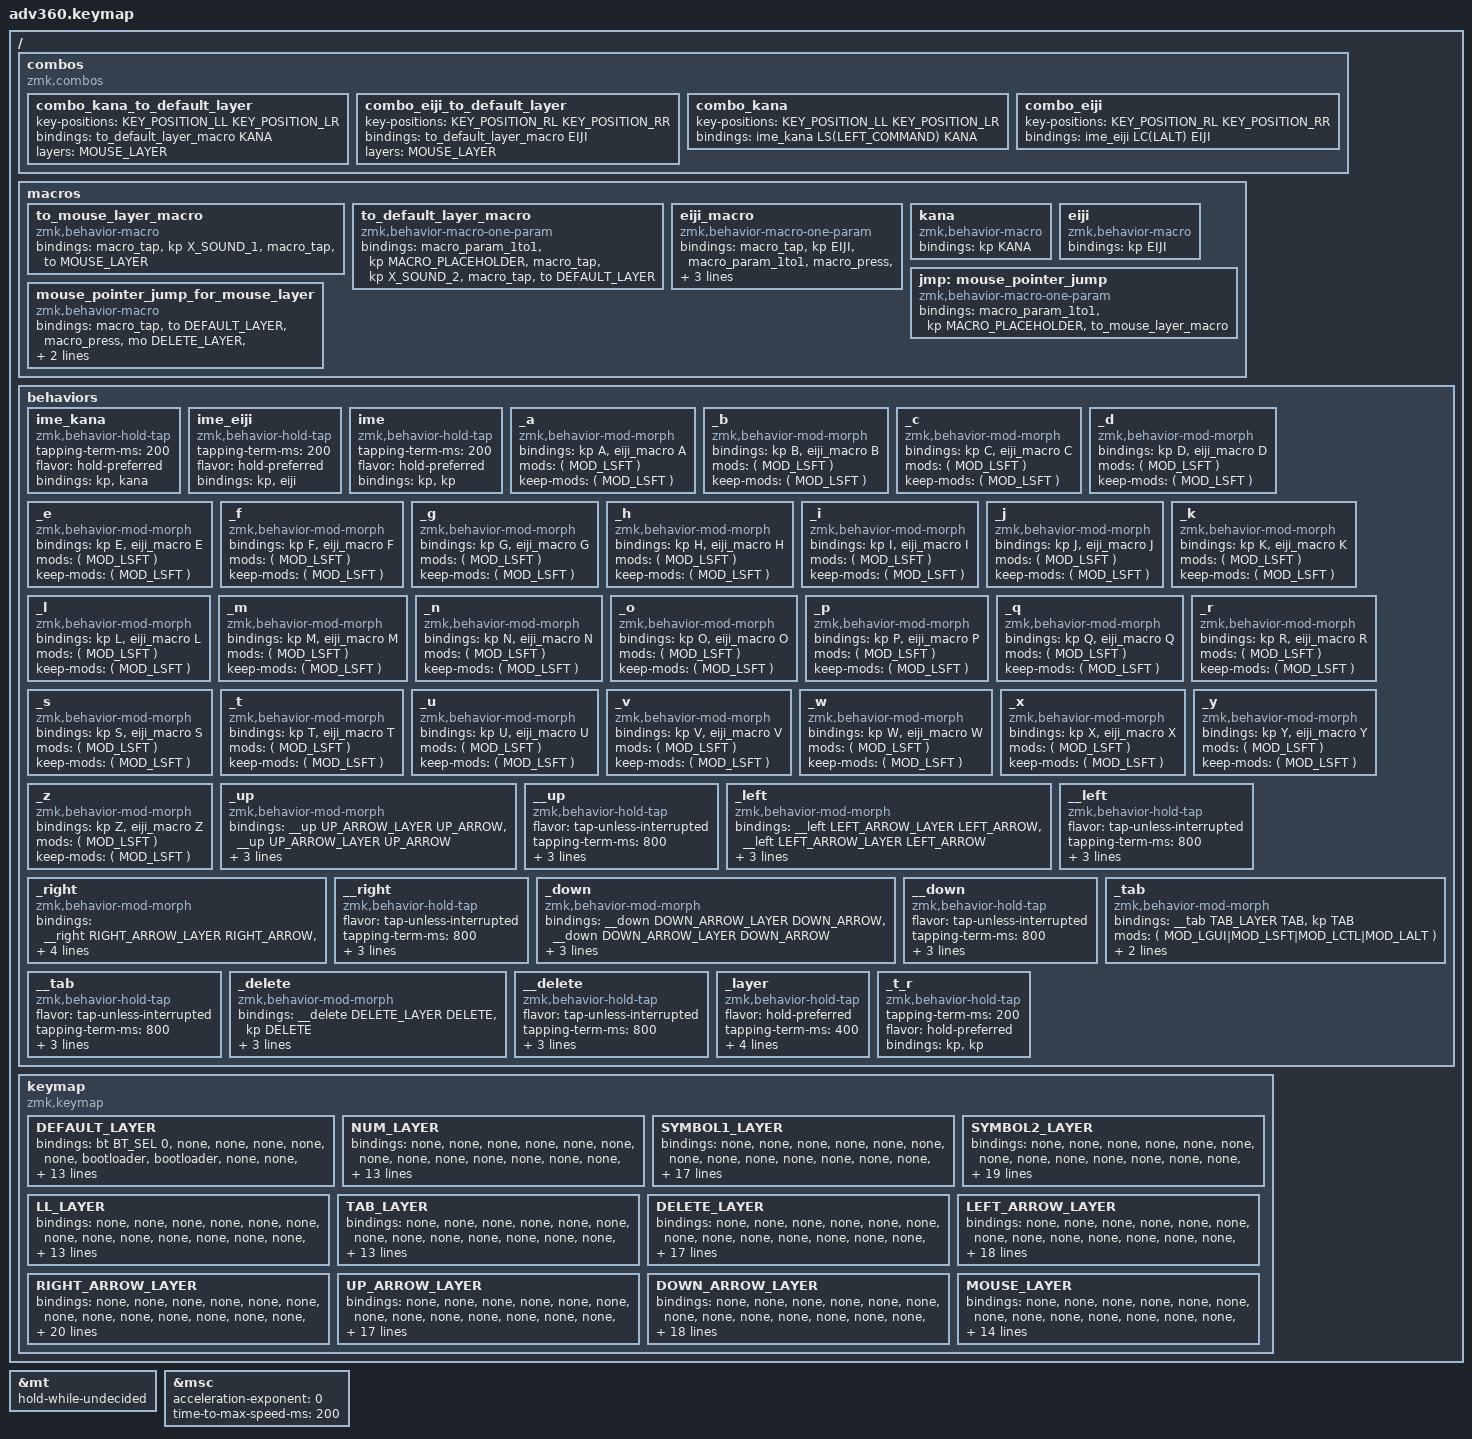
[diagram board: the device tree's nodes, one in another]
#define ZMK_POINTING_DEFAULT_SCRL_VAL 20
#include <behaviors.dtsi>
#include <dt-bindings/zmk/keys.h>
#include <dt-bindings/zmk/bt.h>
#include <dt-bindings/zmk/rgb.h>
#include <dt-bindings/zmk/backlight.h>
#include <dt-bindings/zmk/mouse.h>
#include <dt-bindings/zmk/pointing.h>

// レイヤー
// ------------------------------------
#define DEFAULT_LAYER 0
#define NUM_LAYER 1
#define SYMBOL1_LAYER 2
#define SYMBOL2_LAYER 3
#define LL_LAYER 4
#define TAB_LAYER 5
#define DELETE_LAYER 6
#define LEFT_ARROW_LAYER 7
#define RIGHT_ARROW_LAYER 8
#define UP_ARROW_LAYER 9
#define DOWN_ARROW_LAYER 10
#define MOUSE_LAYER 11

// ------------------------------------
// エイリアス
// ------------------------------------
// 効果音
#define X_SOUND_1 LANGUAGE_3
#define X_SOUND_2 LANGUAGE_4

// 和英
#define EIJI LANGUAGE_2
#define KANA LANGUAGE_1

// 親指
#define T_LL LEFT_SHIFT RETURN
#define T_LR LEFT_COMMAND BACKSPACE

// 和英
#define X_QQ RG(RA(RS(RC(LANGUAGE_8))))
#define X_PP RG(RA(RS(RC(LANGUAGE_9))))

// ------------------------------------
// キー位置
// https://github.com/KinesisCorporation/Adv360-Pro-ZMK/blob/V3.0/assets/key-positions.md
// ------------------------------------
#define KEY_POSITION_LL 65
#define KEY_POSITION_LR 66
#define KEY_POSITION_RL 69
#define KEY_POSITION_RR 70
#define KEY_POSITION_UP_ARROW 56
#define KEY_POSITION_LEFT_ARROW 71
#define KEY_POSITION_DOWN_ARROW 72
#define KEY_POSITION_RIGHT_ARROW 73
#define KEY_POSITION_LEFT_SIDE 0  1  2  3  4  5  6 \
  14 15 16 17 18 19 20 \
  28 29 30 31 32 33 34 \
  46 47 48 49 50 51    \
  60 61 62 63 64
#define KEY_POSITION_RIGHT_SIDE 7  8  9 10 11 12 13 \
  21 22 23 24 25 26 27 \
  39 40 41 42 43 44 45 \
      54 55 56 57 58 59 \
        71 72 73 74 75
#define KEY_POSITION_L_THUMB KEY_POSITION_LL KEY_POSITION_LR

// ------------------------------------
// OSに渡す用ショートカット
// ------------------------------------
#define X_LL_LL KP_N0
#define X_LH_NUM RG(RA(RS(RC(LANGUAGE_5))))
#define X_LH_SYM1 RG(RA(RS(RC(LANGUAGE_6))))
#define X_LH_SYM2 RG(RA(RS(RC(LANGUAGE_7))))

// LL
#define X_LL_AA INTERNATIONAL_1
#define X_LL_ZZ INTERNATIONAL_2
#define X_LL_QQ INTERNATIONAL_3
#define X_LL_NUM INTERNATIONAL_4
#define X_LL_SYM1 INTERNATIONAL_5
#define X_LL_SYM2 INTERNATIONAL_6
#define X_LL_T_LL INTERNATIONAL_7
#define X_LL_T_LR INTERNATIONAL_8
#define X_LL_Q KP_N1
#define X_LL_W KP_N2
#define X_LL_E KP_N3
#define X_LL_R KP_N4
#define X_LL_T KP_N5
#define X_LL_A KP_N6
#define X_LL_S KP_N7
#define X_LL_D KP_N8
#define X_LL_F KP_N9
#define X_LL_G KP_PLUS
#define X_LL_Z KP_EQUAL
#define X_LL_X KP_DOT
#define X_LL_C KP_MINUS
#define X_LL_V KP_SLASH
#define X_LL_B KP_ASTERISK

// TAB: SHIFT ALT
#define X_TAB_AA RS(RA(NON_US_BACKSLASH))
#define X_TAB_ZZ RS(RA(K_APPLICATION))
#define X_TAB_QQ RS(RA(LANGUAGE_5))
#define X_TAB_NUM RS(RA(LANGUAGE_6))
#define X_TAB_SYM1 RS(RA(LANGUAGE_7))
#define X_TAB_SYM2 RS(RA(LANGUAGE_8))
#define X_TAB_T_LL RS(RA(INSERT))
#define X_TAB_T_LR RS(RA(KP_ENTER))
#define X_TAB_Q RS(RA(F13))
#define X_TAB_W RS(RA(F14))
#define X_TAB_E RS(RA(F15))
#define X_TAB_R RS(RA(F16))
#define X_TAB_T RS(RA(F17))
#define X_TAB_A RS(RA(F18))
#define X_TAB_S RS(RA(F19))
#define X_TAB_D RS(RA(F20))
#define X_TAB_F RS(RA(F21))
#define X_TAB_G RS(RA(F22))
#define X_TAB_Z RS(RA(F23))
#define X_TAB_X RS(RA(F24))
#define X_TAB_C RS(RA(NON_US_HASH))
#define X_TAB_V RS(RA(PRINTSCREEN))
#define X_TAB_B RS(RA(PAUSE_BREAK))

// DELETE: SHIFT, COMMAND
#define X_DELETE_AA RS(RG(NON_US_BACKSLASH))
#define X_DELETE_ZZ RS(RG(K_APPLICATION))
#define X_DELETE_QQ RS(RG(LANGUAGE_5))
#define X_DELETE_NUM RS(RG(LANGUAGE_6))
#define X_DELETE_SYM1 RS(RG(LANGUAGE_7))
#define X_DELETE_SYM2 RS(RG(LANGUAGE_8))
#define X_DELETE_T_LL RS(RG(INSERT))
#define X_DELETE_T_LR RS(RG(KP_ENTER))
#define X_DELETE_Q RS(RG(F13))
#define X_DELETE_W RS(RG(F14))
#define X_DELETE_E RS(RG(F15))
#define X_DELETE_R RS(RG(F16))
#define X_DELETE_T RS(RG(F17))
#define X_DELETE_A RS(RG(F18))
#define X_DELETE_S RS(RG(F19))
#define X_DELETE_D RS(RG(F20))
#define X_DELETE_F RS(RG(F21))
#define X_DELETE_G RS(RG(F22))
#define X_DELETE_Z RS(RG(F23))
#define X_DELETE_X RS(RG(F24))
#define X_DELETE_C RS(RG(NON_US_HASH))
#define X_DELETE_V RS(RG(PRINTSCREEN))
#define X_DELETE_B RS(RG(PAUSE_BREAK))

// LEFT_ARROW: ALT, CTRL
#define X_LEFT_ARROW_AA RA(RC(NON_US_BACKSLASH))
#define X_LEFT_ARROW_ZZ RA(RC(K_APPLICATION))
#define X_LEFT_ARROW_QQ RA(RC(LANGUAGE_5))
#define X_LEFT_ARROW_NUM RA(RC(LANGUAGE_6))
#define X_LEFT_ARROW_SYM1 RA(RC(LANGUAGE_7))
#define X_LEFT_ARROW_SYM2 RA(RC(LANGUAGE_8))
#define X_LEFT_ARROW_T_LL RA(RC(INSERT))
#define X_LEFT_ARROW_T_LR RA(RC(KP_ENTER))
#define X_LEFT_ARROW_Q RA(RC(F13))
#define X_LEFT_ARROW_W RA(RC(F14))
#define X_LEFT_ARROW_E RA(RC(F15))
#define X_LEFT_ARROW_R RA(RC(F16))
#define X_LEFT_ARROW_T RA(RC(F17))
#define X_LEFT_ARROW_A RA(RC(F18))
#define X_LEFT_ARROW_S RA(RC(F19))
#define X_LEFT_ARROW_D RA(RC(F20))
#define X_LEFT_ARROW_F RA(RC(F21))
#define X_LEFT_ARROW_G RA(RC(F22))
#define X_LEFT_ARROW_Z RA(RC(F23))
#define X_LEFT_ARROW_X RA(RC(F24))
#define X_LEFT_ARROW_C RA(RC(NON_US_HASH))
#define X_LEFT_ARROW_V RA(RC(PRINTSCREEN))
#define X_LEFT_ARROW_B RA(RC(PAUSE_BREAK))

// RIGHT_ARROW: COMMAND, CTRL
#define X_RIGHT_ARROW_AA RG(RC(NON_US_BACKSLASH))
#define X_RIGHT_ARROW_ZZ RG(RC(K_APPLICATION))
#define X_RIGHT_ARROW_QQ RG(RC(LANGUAGE_5))
#define X_RIGHT_ARROW_NUM RG(RC(LANGUAGE_6))
#define X_RIGHT_ARROW_SYM1 RG(RC(LANGUAGE_7))
#define X_RIGHT_ARROW_SYM2 RG(RC(LANGUAGE_8))
#define X_RIGHT_ARROW_T_LL RG(RC(INSERT))
#define X_RIGHT_ARROW_T_LR RG(RC(KP_ENTER))
#define X_RIGHT_ARROW_Q RG(RC(F13))
#define X_RIGHT_ARROW_W RG(RC(F14))
#define X_RIGHT_ARROW_E RG(RC(F15))
#define X_RIGHT_ARROW_R RG(RC(F16))
#define X_RIGHT_ARROW_T RG(RC(F17))
#define X_RIGHT_ARROW_A RG(RC(F18))
#define X_RIGHT_ARROW_S RG(RC(F19))
#define X_RIGHT_ARROW_D RG(RC(F20))
#define X_RIGHT_ARROW_F RG(RC(F21))
#define X_RIGHT_ARROW_G RG(RC(F22))
#define X_RIGHT_ARROW_Z RG(RC(F23))
#define X_RIGHT_ARROW_X RG(RC(F24))
#define X_RIGHT_ARROW_C RG(RC(NON_US_HASH))
#define X_RIGHT_ARROW_V RG(RC(PRINTSCREEN))
#define X_RIGHT_ARROW_B RG(RC(PAUSE_BREAK))

// UP_ARROW: SHIFT, CTRL
#define X_UP_ARROW_AA RS(RC(NON_US_BACKSLASH))
#define X_UP_ARROW_ZZ RS(RC(K_APPLICATION))
#define X_UP_ARROW_QQ RS(RC(LANGUAGE_5))
#define X_UP_ARROW_NUM RS(RC(LANGUAGE_6))
#define X_UP_ARROW_SYM1 RS(RC(LANGUAGE_7))
#define X_UP_ARROW_SYM2 RS(RC(LANGUAGE_8))
#define X_UP_ARROW_T_LL RS(RC(INSERT))
#define X_UP_ARROW_T_LR RS(RC(KP_ENTER))
#define X_UP_ARROW_Q RS(RC(F13))
#define X_UP_ARROW_W RS(RC(F14))
#define X_UP_ARROW_E RS(RC(F15))
#define X_UP_ARROW_R RS(RC(F16))
#define X_UP_ARROW_T RS(RC(F17))
#define X_UP_ARROW_A RS(RC(F18))
#define X_UP_ARROW_S RS(RC(F19))
#define X_UP_ARROW_D RS(RC(F20))
#define X_UP_ARROW_F RS(RC(F21))
#define X_UP_ARROW_G RS(RC(F22))
#define X_UP_ARROW_Z RS(RC(F23))
#define X_UP_ARROW_X RS(RC(F24))
#define X_UP_ARROW_C RS(RC(NON_US_HASH))
#define X_UP_ARROW_V RS(RC(PRINTSCREEN))
#define X_UP_ARROW_B RS(RC(PAUSE_BREAK))

// DOWN_ARROW: COMMAND, ALT
#define X_DOWN_ARROW_AA RG(RA(NON_US_BACKSLASH))
#define X_DOWN_ARROW_ZZ RG(RA(K_APPLICATION))
#define X_DOWN_ARROW_QQ RG(RA(LANGUAGE_5))
#define X_DOWN_ARROW_NUM RG(RA(LANGUAGE_6))
#define X_DOWN_ARROW_SYM1 RG(RA(LANGUAGE_7))
#define X_DOWN_ARROW_SYM2 RG(RA(LANGUAGE_8))
#define X_DOWN_ARROW_T_LL RG(RA(INSERT))
#define X_DOWN_ARROW_T_LR RG(RA(KP_ENTER))
#define X_DOWN_ARROW_Q RG(RA(F13))
#define X_DOWN_ARROW_W RG(RA(F14))
#define X_DOWN_ARROW_E RG(RA(F15))
#define X_DOWN_ARROW_R RG(RA(F16))
#define X_DOWN_ARROW_T RG(RA(F17))
#define X_DOWN_ARROW_A RG(RA(F18))
#define X_DOWN_ARROW_S RG(RA(F19))
#define X_DOWN_ARROW_D RG(RA(F20))
#define X_DOWN_ARROW_F RG(RA(F21))
#define X_DOWN_ARROW_G RG(RA(F22))
#define X_DOWN_ARROW_Z RG(RA(F23))
#define X_DOWN_ARROW_X RG(RA(F24))
#define X_DOWN_ARROW_C RG(RA(NON_US_HASH))
#define X_DOWN_ARROW_V RG(RA(PRINTSCREEN))
#define X_DOWN_ARROW_B RG(RA(PAUSE_BREAK))

// ------------------------------------
// https://github.com/zmkfirmware/zmk/pull/1811
&mt {
  hold-while-undecided;
};
&msc {
  acceleration-exponent = <0>;
  time-to-max-speed-ms = <200>;
};
/ {
  combos {
    compatible = "zmk,combos";

    combo_kana_to_default_layer {
      key-positions = <KEY_POSITION_LL KEY_POSITION_LR>;
      bindings = <&to_default_layer_macro KANA>;
      layers = <MOUSE_LAYER>;
    };
    combo_eiji_to_default_layer {
      key-positions = <KEY_POSITION_RL KEY_POSITION_RR>;
      bindings = <&to_default_layer_macro EIJI>;
      layers = <MOUSE_LAYER>;
    };
    combo_kana {
      key-positions = <KEY_POSITION_LL KEY_POSITION_LR>;
      bindings = <&ime_kana LS(LEFT_COMMAND) KANA>;
    };
    combo_eiji {
      key-positions = <KEY_POSITION_RL KEY_POSITION_RR>;
      bindings = <&ime_eiji LC(LALT) EIJI>;
    };
  };
  macros {

    // レイヤー移動で効果音を鳴らす
    to_mouse_layer_macro: to_mouse_layer_macro {
      compatible = "zmk,behavior-macro";
      #binding-cells = <0>;
      bindings = <&macro_tap &kp X_SOUND_1>, <&macro_tap &to MOUSE_LAYER>;
    };

    // レイヤー移動で効果音を鳴らす
    to_default_layer_macro: to_default_layer_macro {
      compatible = "zmk,behavior-macro-one-param";
      #binding-cells = <1>;
      bindings = <&macro_param_1to1 &kp MACRO_PLACEHOLDER>, <&macro_tap &kp X_SOUND_2>, <&macro_tap &to DEFAULT_LAYER>;
    };

    // 英語入力に切り替える
    eiji_macro: eiji_macro {
      compatible = "zmk,behavior-macro-one-param";
      #binding-cells = <1>;
      bindings = <&macro_tap &kp EIJI>, <&macro_param_1to1>, <&macro_press &kp MACRO_PLACEHOLDER>, <&macro_pause_for_release>, <&macro_param_1to1>, <&macro_release &kp MACRO_PLACEHOLDER>;
    };
    kana: kana {
      compatible = "zmk,behavior-macro";
      #binding-cells = <0>;
      bindings = <&kp KANA>;
    };
    eiji: eiji {
      compatible = "zmk,behavior-macro";
      #binding-cells = <0>;
      bindings = <&kp EIJI>;
    };

    // マウスのカーソルをジャンプして マウスレイヤーに切り替え
    jmp: mouse_pointer_jump {
      compatible = "zmk,behavior-macro-one-param";
      #binding-cells = <1>;
      bindings = <&macro_param_1to1 &kp MACRO_PLACEHOLDER>, <&to_mouse_layer_macro>;
    };
    mouse_pointer_jump_for_mouse_layer: mouse_pointer_jump_for_mouse_layer {
      compatible = "zmk,behavior-macro";
      #binding-cells = <0>;
      bindings = <&macro_tap &to DEFAULT_LAYER>, <&macro_press &mo DELETE_LAYER>, <&macro_pause_for_release>, <&macro_release &mo DELETE_LAYER>;
    };
  };
  behaviors {
    ime_kana: ime_kana {
      compatible = "zmk,behavior-hold-tap";
      #binding-cells = <2>;
      tapping-term-ms = <200>;
      flavor = "hold-preferred";
      bindings = <&kp>, <&kana>;
    };
    ime_eiji: ime_eiji {
      compatible = "zmk,behavior-hold-tap";
      #binding-cells = <2>;
      tapping-term-ms = <200>;
      flavor = "hold-preferred";
      bindings = <&kp>, <&eiji>;
    };

    // comboから呼ばれる
    ime: ime {
      compatible = "zmk,behavior-hold-tap";
      #binding-cells = <2>;
      tapping-term-ms = <200>;
      flavor = "hold-preferred";
      bindings = <&kp>, <&kp>;
    };
    _a: _a {
      compatible = "zmk,behavior-mod-morph";
      #binding-cells = <0>;
      bindings = <&kp A>, <&eiji_macro A>;
      mods = <( MOD_LSFT )>;
      keep-mods = <( MOD_LSFT )>;
    };
    _b: _b {
      compatible = "zmk,behavior-mod-morph";
      #binding-cells = <0>;
      bindings = <&kp B>, <&eiji_macro B>;
      mods = <( MOD_LSFT )>;
      keep-mods = <( MOD_LSFT )>;
    };
    _c: _c {
      compatible = "zmk,behavior-mod-morph";
      #binding-cells = <0>;
      bindings = <&kp C>, <&eiji_macro C>;
      mods = <( MOD_LSFT )>;
      keep-mods = <( MOD_LSFT )>;
    };
    _d: _d {
      compatible = "zmk,behavior-mod-morph";
      #binding-cells = <0>;
      bindings = <&kp D>, <&eiji_macro D>;
      mods = <( MOD_LSFT )>;
      keep-mods = <( MOD_LSFT )>;
    };
    _e: _e {
      compatible = "zmk,behavior-mod-morph";
      #binding-cells = <0>;
      bindings = <&kp E>, <&eiji_macro E>;
      mods = <( MOD_LSFT )>;
      keep-mods = <( MOD_LSFT )>;
    };
    _f: _f {
      compatible = "zmk,behavior-mod-morph";
      #binding-cells = <0>;
      bindings = <&kp F>, <&eiji_macro F>;
      mods = <( MOD_LSFT )>;
      keep-mods = <( MOD_LSFT )>;
    };
    _g: _g {
      compatible = "zmk,behavior-mod-morph";
      #binding-cells = <0>;
      bindings = <&kp G>, <&eiji_macro G>;
      mods = <( MOD_LSFT )>;
      keep-mods = <( MOD_LSFT )>;
    };
    _h: _h {
      compatible = "zmk,behavior-mod-morph";
      #binding-cells = <0>;
      bindings = <&kp H>, <&eiji_macro H>;
      mods = <( MOD_LSFT )>;
      keep-mods = <( MOD_LSFT )>;
    };
    _i: _i {
      compatible = "zmk,behavior-mod-morph";
      #binding-cells = <0>;
      bindings = <&kp I>, <&eiji_macro I>;
      mods = <( MOD_LSFT )>;
      keep-mods = <( MOD_LSFT )>;
    };
    _j: _j {
      compatible = "zmk,behavior-mod-morph";
      #binding-cells = <0>;
      bindings = <&kp J>, <&eiji_macro J>;
      mods = <( MOD_LSFT )>;
      keep-mods = <( MOD_LSFT )>;
    };
    _k: _k {
      compatible = "zmk,behavior-mod-morph";
      #binding-cells = <0>;
      bindings = <&kp K>, <&eiji_macro K>;
      mods = <( MOD_LSFT )>;
      keep-mods = <( MOD_LSFT )>;
    };
    _l: _l {
      compatible = "zmk,behavior-mod-morph";
      #binding-cells = <0>;
      bindings = <&kp L>, <&eiji_macro L>;
      mods = <( MOD_LSFT )>;
      keep-mods = <( MOD_LSFT )>;
    };
    _m: _m {
      compatible = "zmk,behavior-mod-morph";
      #binding-cells = <0>;
      bindings = <&kp M>, <&eiji_macro M>;
      mods = <( MOD_LSFT )>;
      keep-mods = <( MOD_LSFT )>;
    };
    _n: _n {
      compatible = "zmk,behavior-mod-morph";
      #binding-cells = <0>;
      bindings = <&kp N>, <&eiji_macro N>;
      mods = <( MOD_LSFT )>;
      keep-mods = <( MOD_LSFT )>;
    };
    _o: _o {
      compatible = "zmk,behavior-mod-morph";
      #binding-cells = <0>;
      bindings = <&kp O>, <&eiji_macro O>;
      mods = <( MOD_LSFT )>;
      keep-mods = <( MOD_LSFT )>;
    };
    _p: _p {
      compatible = "zmk,behavior-mod-morph";
      #binding-cells = <0>;
      bindings = <&kp P>, <&eiji_macro P>;
      mods = <( MOD_LSFT )>;
      keep-mods = <( MOD_LSFT )>;
    };
    _q: _q {
      compatible = "zmk,behavior-mod-morph";
      #binding-cells = <0>;
      bindings = <&kp Q>, <&eiji_macro Q>;
      mods = <( MOD_LSFT )>;
      keep-mods = <( MOD_LSFT )>;
    };
    _r: _r {
      compatible = "zmk,behavior-mod-morph";
      #binding-cells = <0>;
      bindings = <&kp R>, <&eiji_macro R>;
      mods = <( MOD_LSFT )>;
      keep-mods = <( MOD_LSFT )>;
    };
    _s: _s {
      compatible = "zmk,behavior-mod-morph";
      #binding-cells = <0>;
      bindings = <&kp S>, <&eiji_macro S>;
      mods = <( MOD_LSFT )>;
      keep-mods = <( MOD_LSFT )>;
    };
    _t: _t {
      compatible = "zmk,behavior-mod-morph";
      #binding-cells = <0>;
      bindings = <&kp T>, <&eiji_macro T>;
      mods = <( MOD_LSFT )>;
      keep-mods = <( MOD_LSFT )>;
    };
    _u: _u {
      compatible = "zmk,behavior-mod-morph";
      #binding-cells = <0>;
      bindings = <&kp U>, <&eiji_macro U>;
      mods = <( MOD_LSFT )>;
      keep-mods = <( MOD_LSFT )>;
    };
    _v: _v {
      compatible = "zmk,behavior-mod-morph";
      #binding-cells = <0>;
      bindings = <&kp V>, <&eiji_macro V>;
      mods = <( MOD_LSFT )>;
      keep-mods = <( MOD_LSFT )>;
    };
    _w: _w {
      compatible = "zmk,behavior-mod-morph";
      #binding-cells = <0>;
      bindings = <&kp W>, <&eiji_macro W>;
      mods = <( MOD_LSFT )>;
      keep-mods = <( MOD_LSFT )>;
    };
    _x: _x {
      compatible = "zmk,behavior-mod-morph";
      #binding-cells = <0>;
      bindings = <&kp X>, <&eiji_macro X>;
      mods = <( MOD_LSFT )>;
      keep-mods = <( MOD_LSFT )>;
    };
    _y: _y {
      compatible = "zmk,behavior-mod-morph";
      #binding-cells = <0>;
      bindings = <&kp Y>, <&eiji_macro Y>;
      mods = <( MOD_LSFT )>;
      keep-mods = <( MOD_LSFT )>;
    };
    _z: _z {
      compatible = "zmk,behavior-mod-morph";
      #binding-cells = <0>;
      bindings = <&kp Z>, <&eiji_macro Z>;
      mods = <( MOD_LSFT )>;
      keep-mods = <( MOD_LSFT )>;
    };
    _up: _up {
      compatible = "zmk,behavior-mod-morph";
      #binding-cells = <0>;
      bindings = <&__up UP_ARROW_LAYER UP_ARROW>, <&__up UP_ARROW_LAYER UP_ARROW>;
      mods = <( MOD_LGUI|MOD_LSFT|MOD_LCTL|MOD_LALT )>;
      keep-mods = <( MOD_LGUI|MOD_LSFT|MOD_LCTL|MOD_LALT )>;
    };
    __up: __up {
      compatible = "zmk,behavior-hold-tap";
      #binding-cells = <2>;
      flavor = "tap-unless-interrupted";
      tapping-term-ms = <800>;
      bindings = <&mo>, <&kp>;
      hold-trigger-key-positions = <KEY_POSITION_LEFT_SIDE KEY_POSITION_L_THUMB KEY_POSITION_LEFT_ARROW KEY_POSITION_RIGHT_ARROW>;
    };
    _left: _left {
      compatible = "zmk,behavior-mod-morph";
      #binding-cells = <0>;
      bindings = <&__left LEFT_ARROW_LAYER LEFT_ARROW>, <&__left LEFT_ARROW_LAYER LEFT_ARROW>;
      mods = <( MOD_LGUI|MOD_LSFT|MOD_LCTL|MOD_LALT )>;
      keep-mods = <( MOD_LGUI|MOD_LSFT|MOD_LCTL|MOD_LALT )>;
    };
    __left: __left {
      compatible = "zmk,behavior-hold-tap";
      #binding-cells = <2>;
      flavor = "tap-unless-interrupted";
      tapping-term-ms = <800>;
      bindings = <&mo>, <&kp>;
      hold-trigger-key-positions = <KEY_POSITION_LEFT_SIDE KEY_POSITION_L_THUMB KEY_POSITION_DOWN_ARROW KEY_POSITION_RIGHT_ARROW>;
    };
    _right: _right {
      compatible = "zmk,behavior-mod-morph";
      #binding-cells = <0>;
      bindings = <&__right RIGHT_ARROW_LAYER RIGHT_ARROW>, <&__right RIGHT_ARROW_LAYER RIGHT_ARROW>;
      mods = <( MOD_LGUI|MOD_LSFT|MOD_LCTL|MOD_LALT )>;
      keep-mods = <( MOD_LGUI|MOD_LSFT|MOD_LCTL|MOD_LALT )>;
    };
    __right: __right {
      compatible = "zmk,behavior-hold-tap";
      #binding-cells = <2>;
      flavor = "tap-unless-interrupted";
      tapping-term-ms = <800>;
      bindings = <&mo>, <&kp>;
      hold-trigger-key-positions = <KEY_POSITION_LEFT_SIDE KEY_POSITION_L_THUMB KEY_POSITION_DOWN_ARROW KEY_POSITION_LEFT_ARROW>;
    };
    _down: _down {
      compatible = "zmk,behavior-mod-morph";
      #binding-cells = <0>;
      bindings = <&__down DOWN_ARROW_LAYER DOWN_ARROW>, <&__down DOWN_ARROW_LAYER DOWN_ARROW>;
      mods = <( MOD_LGUI|MOD_LSFT|MOD_LCTL|MOD_LALT )>;
      keep-mods = <( MOD_LGUI|MOD_LSFT|MOD_LCTL|MOD_LALT )>;
    };
    __down: __down {
      compatible = "zmk,behavior-hold-tap";
      #binding-cells = <2>;
      flavor = "tap-unless-interrupted";
      tapping-term-ms = <800>;
      bindings = <&mo>, <&kp>;
      hold-trigger-key-positions = <KEY_POSITION_LEFT_SIDE KEY_POSITION_L_THUMB KEY_POSITION_LEFT_ARROW KEY_POSITION_RIGHT_ARROW>;
    };
    _tab: _tab {
      compatible = "zmk,behavior-mod-morph";
      #binding-cells = <0>;
      bindings = <&__tab TAB_LAYER TAB>, <&kp TAB>;
      mods = <( MOD_LGUI|MOD_LSFT|MOD_LCTL|MOD_LALT )>;
      keep-mods = <( MOD_LGUI|MOD_LSFT|MOD_LCTL|MOD_LALT )>;
    };
    __tab: __tab {
      compatible = "zmk,behavior-hold-tap";
      #binding-cells = <2>;
      flavor = "tap-unless-interrupted";
      tapping-term-ms = <800>;
      bindings = <&mo>, <&kp>;
      hold-trigger-key-positions = <KEY_POSITION_LEFT_SIDE KEY_POSITION_L_THUMB>;
    };
    _delete: _delete {
      compatible = "zmk,behavior-mod-morph";
      #binding-cells = <0>;
      bindings = <&__delete DELETE_LAYER DELETE>, <&kp DELETE>;
      mods = <( MOD_LGUI|MOD_LSFT|MOD_LCTL|MOD_LALT )>;
      keep-mods = <( MOD_LGUI|MOD_LSFT|MOD_LCTL|MOD_LALT )>;
    };
    __delete: __delete {
      compatible = "zmk,behavior-hold-tap";
      #binding-cells = <2>;
      flavor = "tap-unless-interrupted";
      tapping-term-ms = <800>;
      bindings = <&mo>, <&kp>;
      hold-trigger-key-positions = <KEY_POSITION_LEFT_SIDE KEY_POSITION_L_THUMB>;
    };
    _layer: _layer {
      compatible = "zmk,behavior-hold-tap";
      #binding-cells = <2>;
      flavor = "hold-preferred";
      tapping-term-ms = <400>;
      quick-tap-ms = <200>;
      bindings = <&mo>, <&kp>;
      hold-trigger-key-positions = <KEY_POSITION_RIGHT_SIDE 62 63 64>;
    };
    _t_r: _t_r {
      compatible = "zmk,behavior-hold-tap";
      #binding-cells = <2>;
      tapping-term-ms = <200>;
      flavor = "hold-preferred";
      bindings = <&kp>, <&kp>;
    };
  };
  keymap {
    compatible = "zmk,keymap";

    DEFAULT_LAYER {
      bindings = <
        &bt BT_SEL 0   &none   &none                             &none                             &none                        &none   &bootloader                                                                                         &bootloader   &none   &none    &none    &none     &none                  &bt BT_SEL 1
        &kp X_QQ       &_q     &_w                               &_e                               &_r                          &_t     &none                                                                                               &none         &_y     &_u      &_i      &_o       &_p                    &kp X_PP
        &kp SPACE      &_a     &_s                               &_d                               &_f                          &_g     &none                    &none      &none   &none   &none                                           &none         &_h     &_j      &_k      &_l       &lt LL_LAYER X_LL_LL   &kp BACKSPACE
        &kp ESCAPE     &_z     &_x                               &_c                               &_v                          &_b                                         &none   &none                                                                 &_n     &_m      &_up     &_tab     &_delete               &kp RETURN
        &none          &none   &_layer SYMBOL2_LAYER X_LH_SYM2   &_layer SYMBOL1_LAYER X_LH_SYM1   &_layer NUM_LAYER X_LH_NUM                         &mt T_LL   &mt T_LR   &none   &none   &_t_r LEFT_ALT ESC   &_t_r LEFT_CONTROL SPACE                         &_left   &_down   &_right   &none                  &none
      >;
    };
    NUM_LAYER {
      bindings = <
        &none   &none   &none     &none        &none   &none   &none                                                                                         &none   &none            &none            &none            &none            &none   &none
        &none   &none   &none     &none        &none   &none   &none                                                                                         &none   &none            &eiji_macro N7   &eiji_macro N8   &eiji_macro N9   &none   &none
        &none   &none   &none     &none        &none   &none   &none              &none      &none   &none   &none                                           &none   &none            &eiji_macro N4   &eiji_macro N5   &eiji_macro N6   &none   &none
        &none   &none   &none     &none        &none   &none                                 &none   &none                                                           &eiji_macro N0   &eiji_macro N1   &eiji_macro N2   &eiji_macro N3   &none   &none
        &none   &none   &kp TAB   &kp RETURN   &none                   &mt T_LL   &mt T_LR   &none   &none   &_t_r LEFT_ALT ESC   &_t_r LEFT_CONTROL SPACE                            &none            &none            &none            &none   &none
      >;
    };
    SYMBOL1_LAYER {
      bindings = <
        &none   &none   &none           &none   &none        &none   &none                                                                                         &none   &none                       &none                      &none                   &none                     &none                   &none
        &none   &none   &none           &none   &none        &none   &none                                                                                         &none   &eiji_macro UNDERSCORE      &eiji_macro PIPE           &eiji_macro AMPERSAND   &eiji_macro EXCLAMATION   &eiji_macro QUESTION    &none
        &none   &none   &none           &none   &none        &none   &none              &none      &none   &none   &none                                           &none   &eiji_macro HASH            &eiji_macro COMMA          &eiji_macro PERIOD      &eiji_macro SEMICOLON     &eiji_macro COLON       &eiji_macro AT_SIGN
        &none   &none   &none           &none   &none        &none                                 &none   &none                                                           &eiji_macro DOUBLE_QUOTES   &eiji_macro SINGLE_QUOTE   &eiji_macro GRAVE       &eiji_macro SLASH         &eiji_macro BACKSLASH   &none
        &none   &none   &kp BACKSPACE   &none   &kp DELETE                   &mt T_LL   &mt T_LR   &none   &none   &_t_r LEFT_ALT ESC   &_t_r LEFT_CONTROL SPACE                                       &none                      &none                   &none                     &none                   &none
      >;
    };
    SYMBOL2_LAYER {
      bindings = <
        &none   &none   &none   &none       &none      &none   &none                                                                                         &none   &none               &none                   &none                      &none                      &none                       &none
        &none   &none   &none   &none       &none      &none   &none                                                                                         &none   &eiji_macro CARET   &eiji_macro LESS_THAN   &eiji_macro GREATER_THAN   &eiji_macro LEFT_BRACKET   &eiji_macro RIGHT_BRACKET   &none
        &none   &none   &none   &none       &none      &none   &none              &none      &none   &none   &none                                           &none   &eiji_macro EQUAL   &eiji_macro PLUS        &eiji_macro MINUS          &eiji_macro ASTERISK       &eiji_macro PERCENT         &eiji_macro DOLLAR
        &none   &none   &none   &none       &none      &none                                 &none   &none                                                           &eiji_macro TILDE   &eiji_macro LPAR        &eiji_macro RPAR           &eiji_macro LEFT_BRACE     &eiji_macro RIGHT_BRACE     &none
        &none   &none   &none   &kp LCTRL   &kp LALT                   &mt T_LL   &mt T_LR   &none   &none   &_t_r LEFT_ALT ESC   &_t_r LEFT_CONTROL SPACE                               &none                   &none                      &none                      &none                       &none
      >;
    };
    LL_LAYER {
      bindings = <
        &none         &none        &none           &none           &none          &none        &none                                                                   &none   &none   &none   &none   &none   &none   &none
        &kp X_LL_QQ   &kp X_LL_Q   &kp X_LL_W      &kp X_LL_E      &kp X_LL_R     &kp X_LL_T   &none                                                                   &none   &none   &none   &none   &none   &none   &none
        &kp X_LL_AA   &kp X_LL_A   &kp X_LL_S      &kp X_LL_D      &kp X_LL_F     &kp X_LL_G   &none                   &none           &none   &none   &none           &none   &none   &none   &none   &none   &none   &none
        &kp X_LL_ZZ   &kp X_LL_Z   &kp X_LL_X      &kp X_LL_C      &kp X_LL_V     &kp X_LL_B                                           &none   &none                           &none   &none   &none   &none   &none   &none
        &none         &none        &kp X_LL_SYM2   &kp X_LL_SYM1   &kp X_LL_NUM                        &kp X_LL_T_LL   &kp X_LL_T_LR   &none   &none   &none   &none                   &none   &none   &none   &none   &none
      >;
    };
    TAB_LAYER {
      bindings = <
        &none          &none         &none            &none            &none           &none         &none                                                                     &none   &none   &none   &none   &none   &none   &none
        &kp X_TAB_QQ   &kp X_TAB_Q   &kp X_TAB_W      &kp X_TAB_E      &kp X_TAB_R     &kp X_TAB_T   &none                                                                     &none   &none   &none   &none   &none   &none   &none
        &kp X_TAB_AA   &kp X_TAB_A   &kp X_TAB_S      &kp X_TAB_D      &kp X_TAB_F     &kp X_TAB_G   &none                    &none            &none   &none   &none           &none   &none   &none   &none   &none   &none   &none
        &kp X_TAB_ZZ   &kp X_TAB_Z   &kp X_TAB_X      &kp X_TAB_C      &kp X_TAB_V     &kp X_TAB_B                                             &none   &none                           &none   &none   &none   &none   &none   &none
        &none          &none         &kp X_TAB_SYM2   &kp X_TAB_SYM1   &kp X_TAB_NUM                         &kp X_TAB_T_LL   &kp X_TAB_T_LR   &none   &none   &none   &none                   &none   &none   &none   &none   &none
      >;
    };
    DELETE_LAYER {
      bindings = <
        &none              &none             &none                &none                &none               &none             &none                                                                             &none   &none   &none   &none   &none   &none   &none
        &jmp X_DELETE_QQ   &jmp X_DELETE_Q   &jmp X_DELETE_W      &jmp X_DELETE_E      &jmp X_DELETE_R     &jmp X_DELETE_T   &none                                                                             &none   &none   &none   &none   &none   &none   &none
        &jmp X_DELETE_AA   &jmp X_DELETE_A   &jmp X_DELETE_S      &jmp X_DELETE_D      &jmp X_DELETE_F     &jmp X_DELETE_G   &none                        &none                &none   &none   &none           &none   &none   &none   &none   &none   &none   &none
        &jmp X_DELETE_ZZ   &jmp X_DELETE_Z   &jmp X_DELETE_X      &jmp X_DELETE_C      &jmp X_DELETE_V     &jmp X_DELETE_B                                                     &none   &none                           &none   &none   &none   &none   &none   &none
        &none              &none             &jmp X_DELETE_SYM2   &jmp X_DELETE_SYM1   &jmp X_DELETE_NUM                             &jmp X_DELETE_T_LL   &jmp X_DELETE_T_LR   &none   &none   &none   &none                   &none   &none   &none   &none   &none
      >;
    };
    LEFT_ARROW_LAYER {
      bindings = <
        &none                 &none                &none                   &none                   &none                  &none                &none                                                                                   &none   &none   &none   &none      &none            &none   &none
        &kp X_LEFT_ARROW_QQ   &kp X_LEFT_ARROW_Q   &kp X_LEFT_ARROW_W      &kp X_LEFT_ARROW_E      &kp X_LEFT_ARROW_R     &kp X_LEFT_ARROW_T   &none                                                                                   &none   &none   &none   &none      &none            &none   &none
        &kp X_LEFT_ARROW_AA   &kp X_LEFT_ARROW_A   &kp X_LEFT_ARROW_S      &kp X_LEFT_ARROW_D      &kp X_LEFT_ARROW_F     &kp X_LEFT_ARROW_G   &none                           &none                   &none   &none   &none           &none   &none   &none   &none      &none            &none   &none
        &kp X_LEFT_ARROW_ZZ   &kp X_LEFT_ARROW_Z   &kp X_LEFT_ARROW_X      &kp X_LEFT_ARROW_C      &kp X_LEFT_ARROW_V     &kp X_LEFT_ARROW_B                                                           &none   &none                           &none   &none   &none      &none            &none   &none
        &none                 &none                &kp X_LEFT_ARROW_SYM2   &kp X_LEFT_ARROW_SYM1   &kp X_LEFT_ARROW_NUM                                &kp X_LEFT_ARROW_T_LL   &kp X_LEFT_ARROW_T_LR   &none   &none   &none   &none                   &none   &kp HOME   &msc SCRL_LEFT   &none   &none
      >;
    };
    RIGHT_ARROW_LAYER {
      bindings = <
        &none                  &none                 &none                    &none                    &none                   &none                 &none                                                                                     &none   &none   &none             &none     &none   &none   &none
        &kp X_RIGHT_ARROW_QQ   &kp X_RIGHT_ARROW_Q   &kp X_RIGHT_ARROW_W      &kp X_RIGHT_ARROW_E      &kp X_RIGHT_ARROW_R     &kp X_RIGHT_ARROW_T   &none                                                                                     &none   &none   &none             &none     &none   &none   &none
        &kp X_RIGHT_ARROW_AA   &kp X_RIGHT_ARROW_A   &kp X_RIGHT_ARROW_S      &kp X_RIGHT_ARROW_D      &kp X_RIGHT_ARROW_F     &kp X_RIGHT_ARROW_G   &none                            &none                    &none   &none   &none           &none   &none   &none             &none     &none   &none   &none
        &kp X_RIGHT_ARROW_ZZ   &kp X_RIGHT_ARROW_Z   &kp X_RIGHT_ARROW_X      &kp X_RIGHT_ARROW_C      &kp X_RIGHT_ARROW_V     &kp X_RIGHT_ARROW_B                                                             &none   &none                           &none   &none             &none     &none   &none   &none
        &none                  &none                 &kp X_RIGHT_ARROW_SYM2   &kp X_RIGHT_ARROW_SYM1   &kp X_RIGHT_ARROW_NUM                                 &kp X_RIGHT_ARROW_T_LL   &kp X_RIGHT_ARROW_T_LR   &none   &none   &none   &none                   &msc SCRL_RIGHT   &kp END   &none   &none   &none
      >;
    };
    UP_ARROW_LAYER {
      bindings = <
        &none               &none              &none                 &none                 &none                &none              &none                                                                               &none   &none   &none         &none   &none          &none   &none
        &kp X_UP_ARROW_QQ   &kp X_UP_ARROW_Q   &kp X_UP_ARROW_W      &kp X_UP_ARROW_E      &kp X_UP_ARROW_R     &kp X_UP_ARROW_T   &none                                                                               &none   &none   &none         &none   &none          &none   &none
        &kp X_UP_ARROW_AA   &kp X_UP_ARROW_A   &kp X_UP_ARROW_S      &kp X_UP_ARROW_D      &kp X_UP_ARROW_F     &kp X_UP_ARROW_G   &none                         &none                 &none   &none   &none           &none   &none   &none         &none   &none          &none   &none
        &kp X_UP_ARROW_ZZ   &kp X_UP_ARROW_Z   &kp X_UP_ARROW_X      &kp X_UP_ARROW_C      &kp X_UP_ARROW_V     &kp X_UP_ARROW_B                                                       &none   &none                           &none   &none         &none   &none          &none   &none
        &none               &none              &kp X_UP_ARROW_SYM2   &kp X_UP_ARROW_SYM1   &kp X_UP_ARROW_NUM                              &kp X_UP_ARROW_T_LL   &kp X_UP_ARROW_T_LR   &none   &none   &none   &none                   &kp PAGE_UP   &none   &msc SCRL_UP   &none   &none
      >;
    };
    DOWN_ARROW_LAYER {
      bindings = <
        &none                 &none                &none                   &none                   &none                  &none                &none                                                                                   &none   &none   &none           &none   &none            &none   &none
        &kp X_DOWN_ARROW_QQ   &kp X_DOWN_ARROW_Q   &kp X_DOWN_ARROW_W      &kp X_DOWN_ARROW_E      &kp X_DOWN_ARROW_R     &kp X_DOWN_ARROW_T   &none                                                                                   &none   &none   &none           &none   &none            &none   &none
        &kp X_DOWN_ARROW_AA   &kp X_DOWN_ARROW_A   &kp X_DOWN_ARROW_S      &kp X_DOWN_ARROW_D      &kp X_DOWN_ARROW_F     &kp X_DOWN_ARROW_G   &none                           &none                   &none   &none   &none           &none   &none   &none           &none   &none            &none   &none
        &kp X_DOWN_ARROW_ZZ   &kp X_DOWN_ARROW_Z   &kp X_DOWN_ARROW_X      &kp X_DOWN_ARROW_C      &kp X_DOWN_ARROW_V     &kp X_DOWN_ARROW_B                                                           &none   &none                           &none   &none           &none   &none            &none   &none
        &none                 &none                &kp X_DOWN_ARROW_SYM2   &kp X_DOWN_ARROW_SYM1   &kp X_DOWN_ARROW_NUM                                &kp X_DOWN_ARROW_T_LL   &kp X_DOWN_ARROW_T_LR   &none   &none   &none   &none                   &kp PAGE_DOWN   &none   &msc SCRL_DOWN   &none   &none
      >;
    };
    MOUSE_LAYER {
      bindings = <
        &none        &none   &none            &none            &none             &none   &none                                                                                         &none   &none   &none            &none            &none             &none                                 &none
        &none        &none   &none            &mmv MOVE_UP     &none             &none   &none                                                                                         &none   &none   &none            &none            &none             &none                                 &none
        &kp SPACE    &none   &mmv MOVE_LEFT   &mmv MOVE_DOWN   &mmv MOVE_RIGHT   &none   &none              &none      &none   &none   &none                                           &none   &none   &mkp MB1         &mkp MB2         &mkp MB3          &none                                 &kp BACKSPACE
        &kp ESCAPE   &none   &none            &none            &none             &none                                 &none   &none                                                           &none   &none            &msc SCRL_UP     &none             &mouse_pointer_jump_for_mouse_layer   &kp RETURN
        &none        &none   &none            &none            &none                             &mt T_LL   &mt T_LR   &none   &none   &_t_r LEFT_ALT ESC   &_t_r LEFT_CONTROL SPACE                   &msc SCRL_LEFT   &msc SCRL_DOWN   &msc SCRL_RIGHT   &none                                 &none
      >;
    };
  };
};
